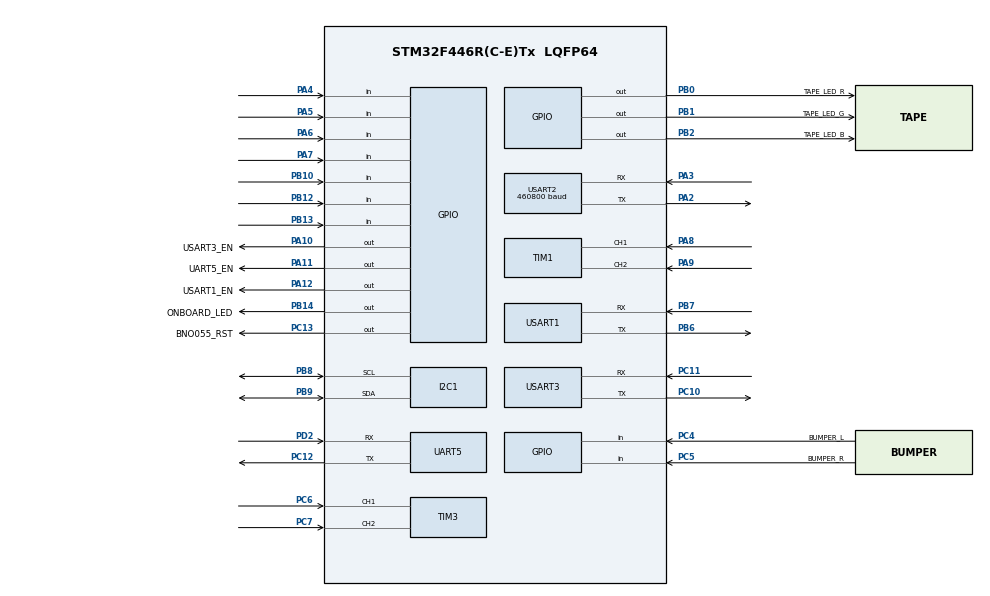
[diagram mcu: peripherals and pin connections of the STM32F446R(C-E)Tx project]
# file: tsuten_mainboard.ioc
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Dma.Request0=USART2_RX
Dma.Request1=USART2_TX
Dma.USART2_RX.0.Direction=DMA_PERIPH_TO_MEMORY
Dma.USART2_RX.0.FIFOMode=DMA_FIFOMODE_DISABLE
Dma.USART2_RX.0.Instance=DMA1_Stream5
Dma.USART2_RX.0.MemDataAlignment=DMA_MDATAALIGN_BYTE
Dma.USART2_RX.0.MemInc=DMA_MINC_ENABLE
Dma.USART2_RX.0.Mode=DMA_CIRCULAR
Dma.USART2_RX.0.PeriphDataAlignment=DMA_PDATAALIGN_BYTE
Dma.USART2_RX.0.PeriphInc=DMA_PINC_DISABLE
Dma.USART2_RX.0.Priority=DMA_PRIORITY_HIGH
Dma.USART2_TX.1.Direction=DMA_MEMORY_TO_PERIPH
Dma.USART2_TX.1.FIFOMode=DMA_FIFOMODE_DISABLE
Dma.USART2_TX.1.Instance=DMA1_Stream6
Dma.USART2_TX.1.MemDataAlignment=DMA_MDATAALIGN_BYTE
Dma.USART2_TX.1.MemInc=DMA_MINC_ENABLE
Dma.USART2_TX.1.Mode=DMA_NORMAL
Dma.USART2_TX.1.PeriphDataAlignment=DMA_PDATAALIGN_BYTE
Dma.USART2_TX.1.PeriphInc=DMA_PINC_DISABLE
Dma.USART2_TX.1.Priority=DMA_PRIORITY_HIGH
Mcu.Family=STM32F4
Mcu.Name=STM32F446R(C-E)Tx
Mcu.Package=LQFP64
NVIC.DMA1_Stream5_IRQn=true\:0\:0\:false\:false\:true\:false\:true\:true
NVIC.DMA1_Stream6_IRQn=true\:0\:0\:false\:false\:true\:false\:true\:true
NVIC.PriorityGroup=NVIC_PRIORITYGROUP_4
NVIC.TIM6_DAC_IRQn=true\:2\:0\:true\:false\:true\:true\:true\:true
NVIC.TIM7_IRQn=true\:3\:0\:true\:false\:true\:true\:true\:true
NVIC.UART5_IRQn=true\:3\:0\:true\:false\:true\:true\:true\:true
NVIC.USART2_IRQn=true\:1\:0\:true\:false\:true\:true\:true\:true
NVIC.USART3_IRQn=true\:3\:0\:true\:false\:true\:true\:true\:true
PA0-WKUP.Signal=USART2_CTS
PA1.Signal=USART2_RTS
PA10.GPIO_Label=USART3_EN
PA10.PinState=GPIO_PIN_SET
PA10.Signal=GPIO_Output
PA11.GPIO_Label=UART5_EN
PA11.PinState=GPIO_PIN_SET
PA11.Signal=GPIO_Output
PA12.GPIO_Label=USART1_EN
PA12.PinState=GPIO_PIN_SET
PA12.Signal=GPIO_Output
PA13.Signal=SYS_JTMS-SWDIO
PA14.Signal=SYS_JTCK-SWCLK
PA2.Mode=Asynchronous
PA2.Signal=USART2_TX
PA3.Mode=Asynchronous
PA3.Signal=USART2_RX
PA4.Signal=GPIO_Input
PA5.Signal=GPIO_Input
PA6.Signal=GPIO_Input
PA7.Signal=GPIO_Input
PA8.Signal=S_TIM1_CH1
PA9.Signal=S_TIM1_CH2
PB0.GPIO_Label=TAPE_LED_R
PB0.Signal=GPIO_Output
PB1.GPIO_Label=TAPE_LED_G
PB1.Signal=GPIO_Output
PB10.Signal=GPIO_Input
PB12.Signal=GPIO_Input
PB13.Signal=GPIO_Input
PB14.GPIO_Label=ONBOARD_LED
PB14.Signal=GPIO_Output
PB2.GPIO_Label=TAPE_LED_B
PB2.Signal=GPIO_Output
PB3.Signal=SYS_JTDO-SWO
PB6.Mode=Asynchronous
PB6.Signal=USART1_TX
PB7.Mode=Asynchronous
PB7.Signal=USART1_RX
PB8.Mode=I2C
PB8.Signal=I2C1_SCL
PB9.Mode=I2C
PB9.Signal=I2C1_SDA
PC10.Mode=Asynchronous
PC10.Signal=USART3_TX
PC11.Mode=Asynchronous
PC11.Signal=USART3_RX
PC12.Mode=Asynchronous
PC12.Signal=UART5_TX
PC13.GPIO_Label=BNO055_RST
PC13.Signal=GPIO_Output
PC4.GPIO_Label=BUMPER_L
PC4.Signal=GPIO_Input
PC5.GPIO_Label=BUMPER_R
PC5.Signal=GPIO_Input
PC6.Signal=S_TIM3_CH1
PC7.Signal=S_TIM3_CH2
PD2.Mode=Asynchronous
PD2.Signal=UART5_RX
PH0-OSC_IN.Mode=HSE-External-Oscillator
PH0-OSC_IN.Signal=RCC_OSC_IN
PH1-OSC_OUT.Mode=HSE-External-Oscillator
PH1-OSC_OUT.Signal=RCC_OSC_OUT
ProjectManager.HeapSize=0x200
ProjectManager.StackSize=0x400
ProjectManager.TargetToolchain=Makefile
RCC.CortexFreq_Value=16000000
RCC.USBFreq_Value=96000000
RCC.VCOOutputFreq_Value=192000000
SH.S_TIM1_CH1.0=TIM1_CH1,Encoder_Interface
SH.S_TIM1_CH2.0=TIM1_CH2,Encoder_Interface
SH.S_TIM3_CH1.0=TIM3_CH1,Encoder_Interface
SH.S_TIM3_CH2.0=TIM3_CH2,Encoder_Interface
TIM1.EncoderMode=TIM_ENCODERMODE_TI12
TIM3.EncoderMode=TIM_ENCODERMODE_TI12
TIM6.Period=100-1
TIM6.Prescaler=16000-1
TIM7.Period=100-1
TIM7.Prescaler=16000-1
UART5.VirtualMode=Asynchronous
USART1.VirtualMode=VM_ASYNC
USART2.BaudRate=460800
USART2.VirtualMode=VM_ASYNC
USART3.VirtualMode=VM_ASYNC
VP_TIM6_VS_ClockSourceINT.Mode=Enable_Timer
VP_TIM7_VS_ClockSourceINT.Mode=Enable_Timer
board=custom

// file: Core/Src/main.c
/* USER CODE BEGIN Header */
/**
 ******************************************************************************
 * @file           : main.c
 * @brief          : Main program body
 ******************************************************************************
 * @attention
 *
 * <h2><center>&copy; Copyright (c) 2023 STMicroelectronics.
 * All rights reserved.</center></h2>
 *
 * This software component is licensed by ST under BSD 3-Clause license,
 * the "License"; You may not use this file except in compliance with the
 * License. You may obtain a copy of the License at:
 *                        opensource.org/licenses/BSD-3-Clause
 *
 ******************************************************************************
 */
/* USER CODE END Header */
#include "main.h"

/* USER CODE BEGIN Includes */
#include "mainpp.h"
/* USER CODE END Includes */

I2C_HandleTypeDef hi2c1;

TIM_HandleTypeDef htim1;
TIM_HandleTypeDef htim3;
TIM_HandleTypeDef htim6;
TIM_HandleTypeDef htim7;

UART_HandleTypeDef huart5;
UART_HandleTypeDef huart1;
UART_HandleTypeDef huart2;
UART_HandleTypeDef huart3;
DMA_HandleTypeDef hdma_usart2_rx;
DMA_HandleTypeDef hdma_usart2_tx;

void SystemClock_Config(void);
static void MX_GPIO_Init(void);
static void MX_DMA_Init(void);
static void MX_I2C1_Init(void);
static void MX_TIM1_Init(void);
static void MX_TIM3_Init(void);
static void MX_USART1_UART_Init(void);
static void MX_USART2_UART_Init(void);
static void MX_USART3_UART_Init(void);
static void MX_UART5_Init(void);
static void MX_TIM6_Init(void);
static void MX_TIM7_Init(void);

int main(void)
{

  /* MCU Configuration--------------------------------------------------------*/

  /* Reset of all peripherals, Initializes the Flash interface and the Systick. */
  HAL_Init();

  /* Configure the system clock */
  SystemClock_Config();

  /* Initialize all configured peripherals */
  MX_GPIO_Init();
  MX_DMA_Init();
  MX_I2C1_Init();
  MX_TIM1_Init();
  MX_TIM3_Init();
  MX_USART1_UART_Init();
  MX_USART2_UART_Init();
  MX_USART3_UART_Init();
  MX_UART5_Init();
  MX_TIM6_Init();
  MX_TIM7_Init();
  /* USER CODE BEGIN 2 */
  setup(&huart5, &huart3, &hi2c1, &htim1, &htim3, &htim6, &htim7);
  /* USER CODE END 2 */

  /* Infinite loop */
  while (1)
  {

    /* USER CODE BEGIN 3 */
    loop();
  }
  /* USER CODE END 3 */
}

void SystemClock_Config(void)
{
  RCC_OscInitTypeDef RCC_OscInitStruct = {0};
  RCC_ClkInitTypeDef RCC_ClkInitStruct = {0};

  /** Configure the main internal regulator output voltage
   */
  __HAL_RCC_PWR_CLK_ENABLE();
  __HAL_PWR_VOLTAGESCALING_CONFIG(PWR_REGULATOR_VOLTAGE_SCALE3);
  /** Initializes the RCC Oscillators according to the specified parameters
   * in the RCC_OscInitTypeDef structure.
   */
  RCC_OscInitStruct.OscillatorType = RCC_OSCILLATORTYPE_HSI;
  RCC_OscInitStruct.HSIState = RCC_HSI_ON;
  RCC_OscInitStruct.HSICalibrationValue = RCC_HSICALIBRATION_DEFAULT;
  RCC_OscInitStruct.PLL.PLLState = RCC_PLL_NONE;
  if (HAL_RCC_OscConfig(&RCC_OscInitStruct) != HAL_OK)
  {
    Error_Handler();
  }
  /** Initializes the CPU, AHB and APB buses clocks
   */
  RCC_ClkInitStruct.ClockType = RCC_CLOCKTYPE_HCLK | RCC_CLOCKTYPE_SYSCLK | RCC_CLOCKTYPE_PCLK1 | RCC_CLOCKTYPE_PCLK2;
  RCC_ClkInitStruct.SYSCLKSource = RCC_SYSCLKSOURCE_HSI;
  RCC_ClkInitStruct.AHBCLKDivider = RCC_SYSCLK_DIV1;
  RCC_ClkInitStruct.APB1CLKDivider = RCC_HCLK_DIV1;
  RCC_ClkInitStruct.APB2CLKDivider = RCC_HCLK_DIV1;

  if (HAL_RCC_ClockConfig(&RCC_ClkInitStruct, FLASH_LATENCY_0) != HAL_OK)
  {
    Error_Handler();
  }
}

static void MX_I2C1_Init(void)
{

  hi2c1.Instance = I2C1;
  hi2c1.Init.ClockSpeed = 100000;
  hi2c1.Init.DutyCycle = I2C_DUTYCYCLE_2;
  hi2c1.Init.OwnAddress1 = 0;
  hi2c1.Init.AddressingMode = I2C_ADDRESSINGMODE_7BIT;
  hi2c1.Init.DualAddressMode = I2C_DUALADDRESS_DISABLE;
  hi2c1.Init.OwnAddress2 = 0;
  hi2c1.Init.GeneralCallMode = I2C_GENERALCALL_DISABLE;
  hi2c1.Init.NoStretchMode = I2C_NOSTRETCH_DISABLE;
  if (HAL_I2C_Init(&hi2c1) != HAL_OK)
  {
    Error_Handler();
  }
}

static void MX_TIM1_Init(void)
{

  TIM_Encoder_InitTypeDef sConfig = {0};
  TIM_MasterConfigTypeDef sMasterConfig = {0};

  htim1.Instance = TIM1;
  htim1.Init.Prescaler = 0;
  htim1.Init.CounterMode = TIM_COUNTERMODE_UP;
  htim1.Init.Period = 65535;
  htim1.Init.ClockDivision = TIM_CLOCKDIVISION_DIV1;
  htim1.Init.RepetitionCounter = 0;
  htim1.Init.AutoReloadPreload = TIM_AUTORELOAD_PRELOAD_DISABLE;
  sConfig.EncoderMode = TIM_ENCODERMODE_TI12;
  sConfig.IC1Polarity = TIM_ICPOLARITY_RISING;
  sConfig.IC1Selection = TIM_ICSELECTION_DIRECTTI;
  sConfig.IC1Prescaler = TIM_ICPSC_DIV1;
  sConfig.IC1Filter = 0;
  sConfig.IC2Polarity = TIM_ICPOLARITY_RISING;
  sConfig.IC2Selection = TIM_ICSELECTION_DIRECTTI;
  sConfig.IC2Prescaler = TIM_ICPSC_DIV1;
  sConfig.IC2Filter = 0;
  if (HAL_TIM_Encoder_Init(&htim1, &sConfig) != HAL_OK)
  {
    Error_Handler();
  }
  sMasterConfig.MasterOutputTrigger = TIM_TRGO_RESET;
  sMasterConfig.MasterSlaveMode = TIM_MASTERSLAVEMODE_DISABLE;
  if (HAL_TIMEx_MasterConfigSynchronization(&htim1, &sMasterConfig) != HAL_OK)
  {
    Error_Handler();
  }
}

static void MX_TIM3_Init(void)
{

  TIM_Encoder_InitTypeDef sConfig = {0};
  TIM_MasterConfigTypeDef sMasterConfig = {0};

  htim3.Instance = TIM3;
  htim3.Init.Prescaler = 0;
  htim3.Init.CounterMode = TIM_COUNTERMODE_UP;
  htim3.Init.Period = 65535;
  htim3.Init.ClockDivision = TIM_CLOCKDIVISION_DIV1;
  htim3.Init.AutoReloadPreload = TIM_AUTORELOAD_PRELOAD_DISABLE;
  sConfig.EncoderMode = TIM_ENCODERMODE_TI12;
  sConfig.IC1Polarity = TIM_ICPOLARITY_RISING;
  sConfig.IC1Selection = TIM_ICSELECTION_DIRECTTI;
  sConfig.IC1Prescaler = TIM_ICPSC_DIV1;
  sConfig.IC1Filter = 0;
  sConfig.IC2Polarity = TIM_ICPOLARITY_RISING;
  sConfig.IC2Selection = TIM_ICSELECTION_DIRECTTI;
  sConfig.IC2Prescaler = TIM_ICPSC_DIV1;
  sConfig.IC2Filter = 0;
  if (HAL_TIM_Encoder_Init(&htim3, &sConfig) != HAL_OK)
  {
    Error_Handler();
  }
  sMasterConfig.MasterOutputTrigger = TIM_TRGO_RESET;
  sMasterConfig.MasterSlaveMode = TIM_MASTERSLAVEMODE_DISABLE;
  if (HAL_TIMEx_MasterConfigSynchronization(&htim3, &sMasterConfig) != HAL_OK)
  {
    Error_Handler();
  }
}

static void MX_TIM6_Init(void)
{

  TIM_MasterConfigTypeDef sMasterConfig = {0};

  htim6.Instance = TIM6;
  htim6.Init.Prescaler = 16000 - 1;
  htim6.Init.CounterMode = TIM_COUNTERMODE_UP;
  htim6.Init.Period = 100 - 1;
  htim6.Init.AutoReloadPreload = TIM_AUTORELOAD_PRELOAD_DISABLE;
  if (HAL_TIM_Base_Init(&htim6) != HAL_OK)
  {
    Error_Handler();
  }
  sMasterConfig.MasterOutputTrigger = TIM_TRGO_RESET;
  sMasterConfig.MasterSlaveMode = TIM_MASTERSLAVEMODE_DISABLE;
  if (HAL_TIMEx_MasterConfigSynchronization(&htim6, &sMasterConfig) != HAL_OK)
  {
    Error_Handler();
  }
}

static void MX_TIM7_Init(void)
{

  TIM_MasterConfigTypeDef sMasterConfig = {0};

  htim7.Instance = TIM7;
  htim7.Init.Prescaler = 16000 - 1;
  htim7.Init.CounterMode = TIM_COUNTERMODE_UP;
  htim7.Init.Period = 100 - 1;
  htim7.Init.AutoReloadPreload = TIM_AUTORELOAD_PRELOAD_DISABLE;
  if (HAL_TIM_Base_Init(&htim7) != HAL_OK)
  {
    Error_Handler();
  }
  sMasterConfig.MasterOutputTrigger = TIM_TRGO_RESET;
  sMasterConfig.MasterSlaveMode = TIM_MASTERSLAVEMODE_DISABLE;
  if (HAL_TIMEx_MasterConfigSynchronization(&htim7, &sMasterConfig) != HAL_OK)
  {
    Error_Handler();
  }
}

static void MX_UART5_Init(void)
{

  huart5.Instance = UART5;
  huart5.Init.BaudRate = 115200;
  huart5.Init.WordLength = UART_WORDLENGTH_8B;
  huart5.Init.StopBits = UART_STOPBITS_1;
  huart5.Init.Parity = UART_PARITY_NONE;
  huart5.Init.Mode = UART_MODE_TX_RX;
  huart5.Init.HwFlowCtl = UART_HWCONTROL_NONE;
  huart5.Init.OverSampling = UART_OVERSAMPLING_16;
  if (HAL_UART_Init(&huart5) != HAL_OK)
  {
    Error_Handler();
  }
}

static void MX_USART1_UART_Init(void)
{

  huart1.Instance = USART1;
  huart1.Init.BaudRate = 115200;
  huart1.Init.WordLength = UART_WORDLENGTH_8B;
  huart1.Init.StopBits = UART_STOPBITS_1;
  huart1.Init.Parity = UART_PARITY_NONE;
  huart1.Init.Mode = UART_MODE_TX_RX;
  huart1.Init.HwFlowCtl = UART_HWCONTROL_NONE;
  huart1.Init.OverSampling = UART_OVERSAMPLING_16;
  if (HAL_UART_Init(&huart1) != HAL_OK)
  {
    Error_Handler();
  }
}

static void MX_USART2_UART_Init(void)
{

  huart2.Instance = USART2;
  huart2.Init.BaudRate = 460800;
  huart2.Init.WordLength = UART_WORDLENGTH_8B;
  huart2.Init.StopBits = UART_STOPBITS_1;
  huart2.Init.Parity = UART_PARITY_NONE;
  huart2.Init.Mode = UART_MODE_TX_RX;
  huart2.Init.HwFlowCtl = UART_HWCONTROL_NONE;
  huart2.Init.OverSampling = UART_OVERSAMPLING_16;
  if (HAL_UART_Init(&huart2) != HAL_OK)
  {
    Error_Handler();
  }
}

static void MX_USART3_UART_Init(void)
{

  huart3.Instance = USART3;
  huart3.Init.BaudRate = 115200;
  huart3.Init.WordLength = UART_WORDLENGTH_8B;
  huart3.Init.StopBits = UART_STOPBITS_1;
  huart3.Init.Parity = UART_PARITY_NONE;
  huart3.Init.Mode = UART_MODE_TX_RX;
  huart3.Init.HwFlowCtl = UART_HWCONTROL_NONE;
  huart3.Init.OverSampling = UART_OVERSAMPLING_16;
  if (HAL_UART_Init(&huart3) != HAL_OK)
  {
    Error_Handler();
  }
}

static void MX_DMA_Init(void)
{

  /* DMA controller clock enable */
  __HAL_RCC_DMA1_CLK_ENABLE();

  /* DMA interrupt init */
  /* DMA1_Stream5_IRQn interrupt configuration */
  HAL_NVIC_SetPriority(DMA1_Stream5_IRQn, 0, 0);
  HAL_NVIC_EnableIRQ(DMA1_Stream5_IRQn);
  /* DMA1_Stream6_IRQn interrupt configuration */
  HAL_NVIC_SetPriority(DMA1_Stream6_IRQn, 0, 0);
  HAL_NVIC_EnableIRQ(DMA1_Stream6_IRQn);
}

static void MX_GPIO_Init(void)
{
  GPIO_InitTypeDef GPIO_InitStruct = {0};

  /* GPIO Ports Clock Enable */
  __HAL_RCC_GPIOC_CLK_ENABLE();
  __HAL_RCC_GPIOH_CLK_ENABLE();
  __HAL_RCC_GPIOA_CLK_ENABLE();
  __HAL_RCC_GPIOB_CLK_ENABLE();
  __HAL_RCC_GPIOD_CLK_ENABLE();

  /*Configure GPIO pin Output Level */
  HAL_GPIO_WritePin(BNO055_RST_GPIO_Port, BNO055_RST_Pin, GPIO_PIN_RESET);

  /*Configure GPIO pin Output Level */
  HAL_GPIO_WritePin(GPIOB, TAPE_LED_R_Pin | TAPE_LED_G_Pin | TAPE_LED_B_Pin | ONBOARD_LED_Pin, GPIO_PIN_RESET);

  /*Configure GPIO pin Output Level */
  HAL_GPIO_WritePin(GPIOA, USART3_EN_Pin | UART5_EN_Pin | USART1_EN_Pin, GPIO_PIN_SET);

  /*Configure GPIO pin : BNO055_RST_Pin */
  GPIO_InitStruct.Pin = BNO055_RST_Pin;
  GPIO_InitStruct.Mode = GPIO_MODE_OUTPUT_PP;
  GPIO_InitStruct.Pull = GPIO_NOPULL;
  GPIO_InitStruct.Speed = GPIO_SPEED_FREQ_LOW;
  HAL_GPIO_Init(BNO055_RST_GPIO_Port, &GPIO_InitStruct);

  /*Configure GPIO pins : PA4 PA5 PA6 PA7 */
  GPIO_InitStruct.Pin = GPIO_PIN_4 | GPIO_PIN_5 | GPIO_PIN_6 | GPIO_PIN_7;
  GPIO_InitStruct.Mode = GPIO_MODE_INPUT;
  GPIO_InitStruct.Pull = GPIO_NOPULL;
  HAL_GPIO_Init(GPIOA, &GPIO_InitStruct);

  /*Configure GPIO pins : BUMPER_L_Pin BUMPER_R_Pin */
  GPIO_InitStruct.Pin = BUMPER_L_Pin | BUMPER_R_Pin;
  GPIO_InitStruct.Mode = GPIO_MODE_INPUT;
  GPIO_InitStruct.Pull = GPIO_NOPULL;
  HAL_GPIO_Init(GPIOC, &GPIO_InitStruct);

  /*Configure GPIO pins : TAPE_LED_R_Pin TAPE_LED_G_Pin TAPE_LED_B_Pin ONBOARD_LED_Pin */
  GPIO_InitStruct.Pin = TAPE_LED_R_Pin | TAPE_LED_G_Pin | TAPE_LED_B_Pin | ONBOARD_LED_Pin;
  GPIO_InitStruct.Mode = GPIO_MODE_OUTPUT_PP;
  GPIO_InitStruct.Pull = GPIO_NOPULL;
  GPIO_InitStruct.Speed = GPIO_SPEED_FREQ_LOW;
  HAL_GPIO_Init(GPIOB, &GPIO_InitStruct);

  /*Configure GPIO pins : PB10 PB12 PB13 */
  GPIO_InitStruct.Pin = GPIO_PIN_10 | GPIO_PIN_12 | GPIO_PIN_13;
  GPIO_InitStruct.Mode = GPIO_MODE_INPUT;
  GPIO_InitStruct.Pull = GPIO_NOPULL;
  HAL_GPIO_Init(GPIOB, &GPIO_InitStruct);

  /*Configure GPIO pins : USART3_EN_Pin UART5_EN_Pin USART1_EN_Pin */
  GPIO_InitStruct.Pin = USART3_EN_Pin | UART5_EN_Pin | USART1_EN_Pin;
  GPIO_InitStruct.Mode = GPIO_MODE_OUTPUT_PP;
  GPIO_InitStruct.Pull = GPIO_NOPULL;
  GPIO_InitStruct.Speed = GPIO_SPEED_FREQ_LOW;
  HAL_GPIO_Init(GPIOA, &GPIO_InitStruct);
}

void Error_Handler(void)
{
  __disable_irq();
  while (1)
  {
  }
}

/************************ (C) COPYRIGHT STMicroelectronics *****END OF FILE****/
